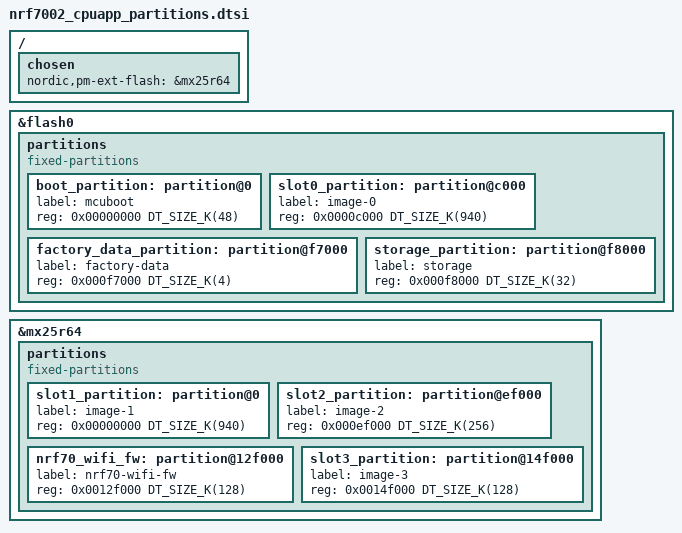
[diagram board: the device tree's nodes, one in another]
/*
 * Copyright (c) 2026 Nordic Semiconductor ASA
 *
 * SPDX-License-Identifier: LicenseRef-Nordic-5-Clause
 *
 */

/delete-node/ &boot_partition;
/delete-node/ &slot0_partition;
/delete-node/ &slot1_partition;
/delete-node/ &storage_partition;

/ {
	chosen {
		nordic,pm-ext-flash = &mx25r64;
	};
};

&flash0 {
	partitions {
		compatible = "fixed-partitions";
		#address-cells = <1>;
		#size-cells = <1>;

		boot_partition: partition@0 {
			label = "mcuboot";
			reg = <0x00000000 DT_SIZE_K(48)>;
		};

		slot0_partition: partition@c000 {
			label = "image-0";
			reg = <0x0000c000 DT_SIZE_K(940)>;
		};

		factory_data_partition: partition@f7000 {
			label = "factory-data";
			reg = <0x000f7000 DT_SIZE_K(4)>;
		};

		storage_partition: partition@f8000 {
			label = "storage";
			reg = <0x000f8000 DT_SIZE_K(32)>;
		};
	};
};

&mx25r64 {
	status = "okay";

	partitions {
		compatible = "fixed-partitions";
		#address-cells = <1>;
		#size-cells = <1>;

		slot1_partition: partition@0 {
			label = "image-1";
			reg = <0x00000000 DT_SIZE_K(940)>;
		};

		slot2_partition: partition@ef000 {
			label = "image-2";
			reg = <0x000ef000 DT_SIZE_K(256)>;
		};

        nrf70_wifi_fw: partition@12f000 {
            label = "nrf70-wifi-fw";
            reg = <0x0012f000 DT_SIZE_K(128)>;
        };

		slot3_partition: partition@14f000 {
			label = "image-3";
			reg = <0x0014f000 DT_SIZE_K(128)>;
		};
	};
};
